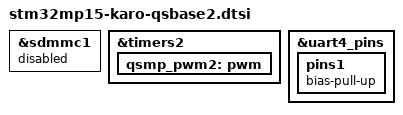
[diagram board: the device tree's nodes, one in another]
// SPDX-License-Identifier: GPL-2.0 OR BSD-3-Clause
/*
 * Copyright (C) 2020 Markus Bauer <mb@karo-electronics.de>
 */

/ {
	/delete-node/ sound;
};

&sdmmc1 {
	status = "disabled";
};

&timers2 {
	status = "okay";

	qsmp_pwm2: pwm {
		status = "okay";
	};
};

&uart4_pins {
	pins1 {
		/delete-property/ bias-disable;
		bias-pull-up;
	};
};
